# max32665 register map
Vendor: Maxim-Integrated; Series: ARMCM3; File version: 1.1
CPU: CM4 r2p1, little endian, MPU, FPU, 3 interrupt priority bits
Registers are 32-bit, read-write, reset 0x0 unless marked. A register's access mark holds for its fields unless they carry their own. Offsets are from the block's base; [hi:lo] are bit positions; {n}, {i} and the like mark numbered series.

## ADC — 10-bit Analog to Digital Converter
Base 0x40034000
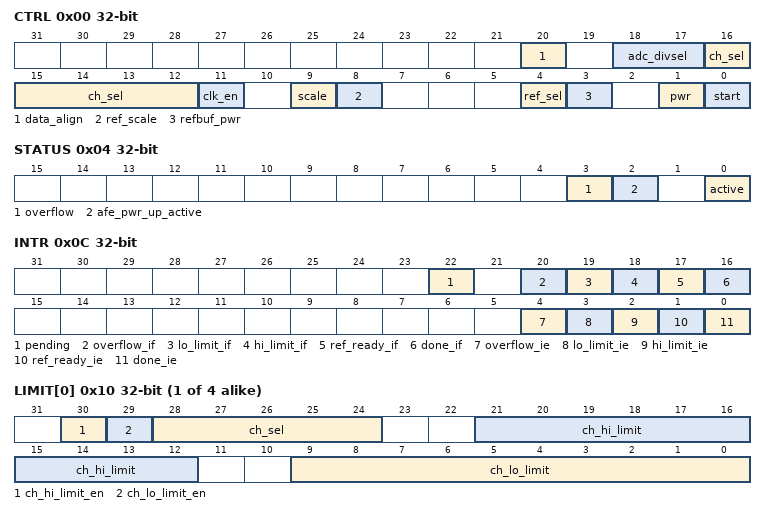
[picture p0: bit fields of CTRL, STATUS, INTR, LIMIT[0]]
0x00 CTRL — ADC Control
  [20] data_align — ADC Data Alignment Select
  [18:17] adc_divsel — Scales the external inputs, all inputs are scaled the same
    {v}=DIV{v+1} (v=0..3)
  [16:12] ch_sel — ADC Channel Select
    {v}=AIN{v} (v=0..7); 8=VcoreA; 9=VcoreB; 10=Vrxout; 11=Vtxout; 12=VddA; 13=VddB/4; 14=Vddio/4; 15=Vddioh/4; 16=VregI/4
  [11] clk_en — ADC Clock Enable
  [9] scale — ADC Scale
  [8] ref_scale — ADC Reference Scale
  [4] ref_sel — ADC Reference Select
  [3] refbuf_pwr — ADC Reference Buffer Power Up
  [1] pwr — ADC Power Up
  [0] start — Start ADC Conversion
0x04 STATUS — ADC Status
  [3] overflow ro — ADC Overflow
  [2] afe_pwr_up_active ro — AFE Power Up Delay Active
  [0] active ro — ADC Conversion In Progress
0x08 DATA — ADC Output Data
  [15:0] data ro — ADC Converted Sample Data Output
0x0C INTR — ADC Interrupt Control Register
  [22] pending ro — ADC Interrupt Pending Status
  [20] overflow_if write-1-clears — ADC Overflow Interrupt Flag
  [19] lo_limit_if write-1-clears — ADC Lo Limit Monitor Interrupt Flag
  [18] hi_limit_if write-1-clears — ADC Hi Limit Monitor Interrupt Flag
  [17] ref_ready_if write-1-clears — ADC Reference Ready Interrupt Flag
  [16] done_if write-1-clears — ADC Done Interrupt Flag
  [4] overflow_ie — ADC Overflow Interrupt Enable
  [3] lo_limit_ie — ADC Lo Limit Monitor Interrupt Enable
  [2] hi_limit_ie — ADC Hi Limit Monitor Interrupt Enable
  [1] ref_ready_ie — ADC Reference Ready Interrupt Enable
  [0] done_ie — ADC Done Interrupt Enable
{0x10+4i} LIMIT[{i}] (i=0..3) — ADC Limit
  [30] ch_hi_limit_en — High Limit Monitoring Enable
  [29] ch_lo_limit_en — Low Limit Monitoring Enable
  [28:24] ch_sel — ADC Channel Select
  [21:12] ch_hi_limit — High Limit Threshold
  [9:0] ch_lo_limit — Low Limit Threshold

## AESKEYS — AES Key Registers.
Base 0x40005000
{0x0+0x80*i} KEY{i} (i=0..3) — AES Key {i}.

## FCR — Function Control.
Base 0x40000800
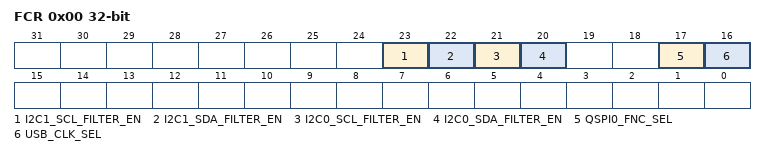
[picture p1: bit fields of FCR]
0x00 FCR — Register 0.
  [23] I2C1_SCL_FILTER_EN — I2C1 SCL Pad Deglitcher enable.
    0=dis (Deglitcher disabled.); 1=en (Deglitcher enabled.)
  [22] I2C1_SDA_FILTER_EN — I2C1 SDA Pad Deglitcher enable.
    0=dis (Deglitcher disabled.); 1=en (Deglitcher enabled.)
  [21] I2C0_SCL_FILTER_EN — I2C0 SCL Pad Deglitcher enable.
    0=dis (Deglitcher disabled.); 1=en (Deglitcher enabled.)
  [20] I2C0_SDA_FILTER_EN — I2C0 SDA Pad Deglitcher enable.
    0=dis (Deglitcher disabled.); 1=en (Deglitcher enabled.)
  [17] QSPI0_FNC_SEL — SPI0 Function Select.
    0=hirc (High speed 96MHz oscillator.); 1=ext_clk (External clock input.)
  [16] USB_CLK_SEL — USB External Core Clock Select.
    0=sys (Generated clock from system clock.); 1=dig (Digital clock from a GPIO.)

## FLC — Flash Memory Control.
Base 0x40029000; register names take the prefix FLSH_
Same registers: FLC1 0x40029400
0x00 ADDR — Flash Write Address.
  [31:0] ADDR — Address for next operation.
0x04 CLKDIV reset 0x64 — Flash Clock Divide. The clock (PLL0) is divided by this value to generate a 1 MHz clock for Flash controller.
  [7:0] CLKDIV — Flash Clock Divide. The clock is divided by this value to generate a 1MHz clock for flash controller.
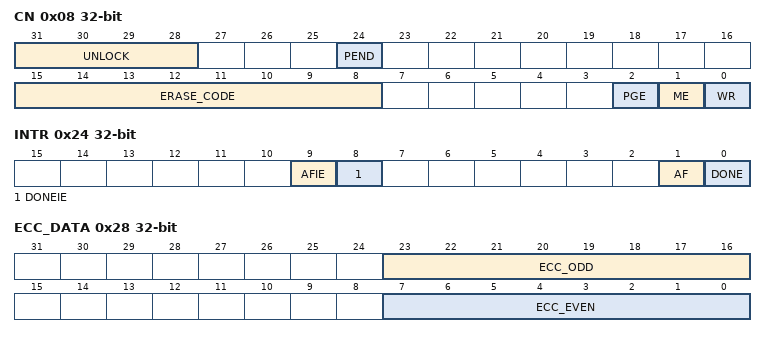
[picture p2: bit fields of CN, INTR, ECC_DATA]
0x08 CN — Flash Control Register.
  [31:28] UNLOCK — Flash Unlock. The correct unlock code must be written to these four bits before any Flash write or erase operation is allowed.
    2=unlocked (Flash Unlocked.); 3=locked (Flash Locked.)
  [24] PEND ro — Flash Pending. When Flash operation is in progress (busy), Flash reads and writes will fail. When PEND is set, write to all Flash registers, with exception of the Flash interrupt register, are ignored.
    0=idle; 1=busy
  [15:8] ERASE_CODE — Erase Code. The ERASE_CODE must be set up property before erase operation can be initiated. These bits are automatically cleared after the operation is complete.
    0=nop (No operation.); 85=erasePage (Enable Page Erase.); 170=eraseAll (Enable Mass Erase. The debug port must be enabled.)
  [2] PGE — Page Erase. This bit is automatically cleared after the operation.
    0=complete (No operation/complete.); 1=Start operation
  [1] ME — Mass Erase. This bit is automatically cleared after the operation.
    0=complete (No operation/complete.); 1=Start operation
  [0] WR — Write. This bit is automatically cleared after the operation.
    0=complete (No operation/complete.); 1=Start operation
0x24 INTR — Flash Interrupt Register.
  [9] AFIE — Flash Done Interrupt Enable.
    0=disable; 1=enable
  [8] DONEIE — Flash Done Interrupt Enable.
    0=disable; 1=enable
  [1] AF — Flash Access Fail. This bit is set when an attempt is made to write the flash while the flash is busy or the flash is locked. This bit can only be set to 1 by hardware.
    0=noError (No Failure.); 1=error (Failure occurs.)
  [0] DONE — Flash Done Interrupt. This bit is set to 1 upon Flash write or erase completion.
    0=inactive (No interrupt is pending.); 1=pending (An interrupt is pending.)
0x28 ECC_DATA ro — Flash Controller ECC Data Register.
  [23:16] ECC_ODD — Error Correction Code Odd Data.
  [7:0] ECC_EVEN — Error Correction Code Even Data.
{0x30+4i} DATA[{i}] (i=0..3) — Flash Write Data.
  [31:0] DATA — Data next operation.
0x40 ACTNL wo — Access Control Register. Writing the ACNTL register with the following values in the order shown, allows read and write access to the system and user Information block: pflc-acntl = 0x3a7f5ca3; pflc-acntl = 0xa1e34f20; pflc-acntl = 0x9608b2c1. When unlocked, a write of any word will disable access to system and user information block. Readback of this register is always zero.
  [31:0] ACNTL — Access control.
